# RTC register map
Registers from a debugger description file.
Registers are 32-bit, access not given, no defined reset value unless marked. A register's access mark holds for its fields unless they carry their own. Addresses are absolute; registers are grouped by the start of their names; lines under a group give offsets from that group; [hi:lo] are bit positions; {n}, {i} and the like mark numbered series; 'fields as' and 'values as' point back to an identical list; <NAME> marks a mode.

## SFR
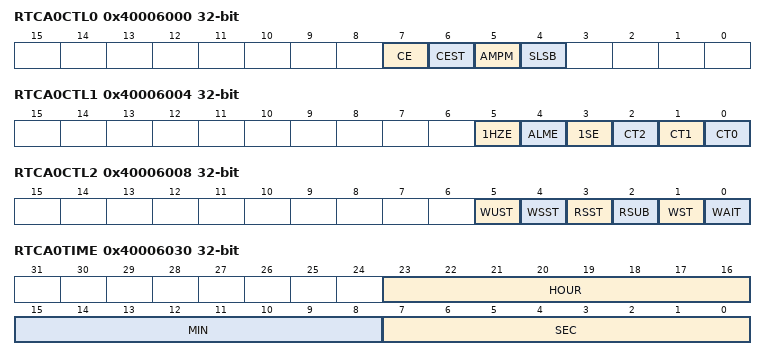
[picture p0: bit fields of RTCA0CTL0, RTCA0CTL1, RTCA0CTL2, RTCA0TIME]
0x40006000 RTCA0CTL0
  [7] CE, [6] CEST, [5] AMPM, [4] SLSB
0x40006004 RTCA0CTL1
  [5] 1HZE, [4] ALME, [3] 1SE, [2] CT2, [1] CT1, [0] CT0
0x40006008 RTCA0CTL2
  [5] WUST, [4] WSST, [3] RSST, [2] RSUB, [1] WST, [0] WAIT
0x4000600C RTCA0SUBC ro
  [21:0] SUBC
0x40006010 RTCA0SRBU ro
  [21:0] SRBU
0x40006014 RTCA0SEC
  [6:0] SEC
0x40006018 RTCA0MIN
  [6:0] MIN
0x4000601C RTCA0HOUR
  [5:0] HOUR
0x40006020 RTCA0WEEK
  [2:0] WEEK
0x40006024 RTCA0DAY
  [5:0] DAY
0x40006028 RTCA0MONTH
  [4:0] MONTH
0x4000602C RTCA0YEAR
  [7:0] YEAR
0x40006030 RTCA0TIME
  [23:16] HOUR, [15:8] MIN, [7:0] SEC
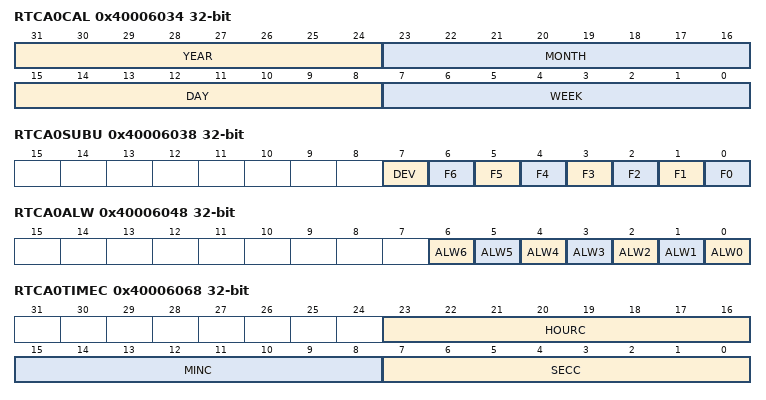
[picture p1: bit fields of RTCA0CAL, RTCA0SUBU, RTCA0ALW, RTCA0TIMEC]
0x40006034 RTCA0CAL
  [31:24] YEAR, [23:16] MONTH, [15:8] DAY, [7:0] WEEK
0x40006038 RTCA0SUBU
  [7] DEV, [n] F{n} (n=0..6)
0x4000603C RTCA0SCMP
  [21:0] SCMP
0x40006040 RTCA0ALM
  [6:0] ALM
0x40006044 RTCA0ALH
  [5:0] ALH
0x40006048 RTCA0ALW
  [n] ALW{n} (n=0..6)
0x4000604C RTCA0SECC ro
  [6:0] SECC
0x40006050 RTCA0MINC ro
  [6:0] MINC
0x40006054 RTCA0HOURC ro
  [5:0] HOURC
0x40006058 RTCA0WEEKC ro
  [2:0] WEEKC
0x4000605C RTCA0DAYC ro
  [5:0] DAYC
0x40006060 RTCA0MONC ro
  [4:0] MONC
0x40006064 RTCA0YEARC ro
  [7:0] YEARC
0x40006068 RTCA0TIMEC ro
  [23:16] HOURC, [15:8] MINC, [7:0] SECC
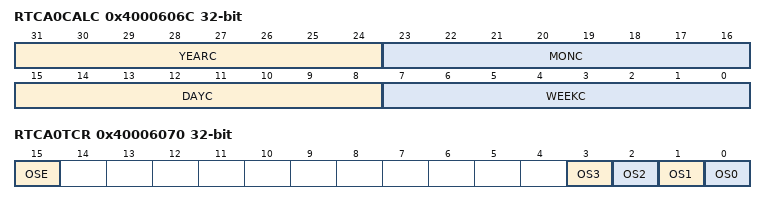
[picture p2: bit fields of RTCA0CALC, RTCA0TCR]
0x4000606C RTCA0CALC ro
  [31:24] YEARC, [23:16] MONC, [15:8] DAYC, [7:0] WEEKC
0x40006070 RTCA0TCR
  [15] OSE, [n] OS{n} (n=0..3)
0x40006074 RTCA0EMU
  [7] SVSDIS
